AUTOSAR XML (schema 4-2-2)
package /STELLANTIS/EPT/ASWCs
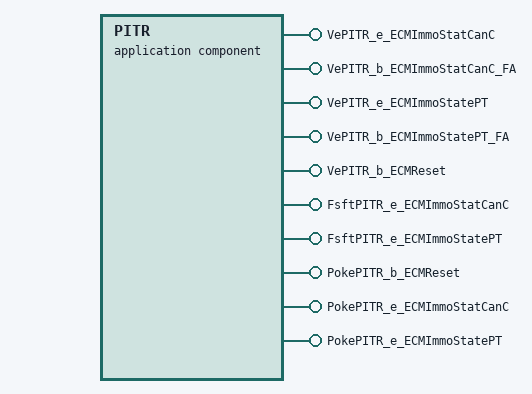
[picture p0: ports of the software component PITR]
  application sw component type PITR
    10 x provide port:
      VePITR_e_ECMImmoStatCanC: nonqueued-sender-com-spec{data-element=Value, init-value=CeIMOR_e_ECMcIS}, provided-interface=VePITR_e_ECMImmoStatCanC
      VePITR_b_ECMImmoStatCanC_FA: nonqueued-sender-com-spec{data-element=Value, init-value=0}, provided-interface=VePITR_b_ECMImmoStatCanC_FA
      VePITR_e_ECMImmoStatePT: nonqueued-sender-com-spec{data-element=Value, init-value=CeIMOR_e_ECMeIS}, provided-interface=VePITR_e_ECMImmoStatePT
      VePITR_b_ECMImmoStatePT_FA: nonqueued-sender-com-spec{data-element=Value, init-value=0}, provided-interface=VePITR_b_ECMImmoStatePT_FA
      VePITR_b_ECMReset: nonqueued-sender-com-spec{data-element=Value, init-value=0}, provided-interface=VePITR_b_ECMReset
      FsftPITR_e_ECMImmoStatCanC: server-com-spec=FsftPITR_e_ECMImmoStatCanC, provided-interface=FsftPITR_e_ECMImmoStatCanC
      FsftPITR_e_ECMImmoStatePT: server-com-spec=FsftPITR_e_ECMImmoStatePT, provided-interface=FsftPITR_e_ECMImmoStatePT
      PokePITR_b_ECMReset: server-com-spec{operation=PokePITR_b_ECMReset, queue-length=1}, provided-interface=PokePITR_b_ECMReset
      PokePITR_e_ECMImmoStatCanC: server-com-spec{operation=PokePITR_e_ECMImmoStatCanC, queue-length=1}, provided-interface=PokePITR_e_ECMImmoStatCanC
      PokePITR_e_ECMImmoStatePT: server-com-spec{operation=PokePITR_e_ECMImmoStatePT, queue-length=1}, provided-interface=PokePITR_e_ECMImmoStatePT
    behavior IB_PITR: data-type-mapping=msADTtoIDTMapping, handle-termination-and-restart=NO-SUPPORT
      5 x operation invoked event:
        Event_FsftPITR_e_ECMImmoStatCanC: start-on-event=FsftPITR_e_ECMImmoStatCanC, operation=FsftPITR_e_ECMImmoStatCanC.FsftPITR_e_ECMImmoStatCanC
        Event_FsftPITR_e_ECMImmoStatePT: start-on-event=FsftPITR_e_ECMImmoStatePT, operation=FsftPITR_e_ECMImmoStatePT.FsftPITR_e_ECMImmoStatePT
        Event_PokePITR_b_ECMReset: start-on-event=PokePITR_b_ECMReset, operation=PokePITR_b_ECMReset.PokePITR_b_ECMReset
        Event_PokePITR_e_ECMImmoStatCanC: start-on-event=PokePITR_e_ECMImmoStatCanC, operation=PokePITR_e_ECMImmoStatCanC.PokePITR_e_ECMImmoStatCanC
        Event_PokePITR_e_ECMImmoStatePT: start-on-event=PokePITR_e_ECMImmoStatePT, operation=PokePITR_e_ECMImmoStatePT.PokePITR_e_ECMImmoStatePT
      init event Event_PITR_ac_Init: start-on-event=PITR_ac_Init
      init event Event_PwrOn: start-on-event=PITR_PwrOn
      7 x runnable:
        PITR_ac_Init
          data-send-points:
            access OUT_VePITR_e_ECMImmoStatCanC_Value: accessed-variable=VePITR_e_ECMImmoStatCanC.Value
            access OUT_VePITR_e_ECMImmoStatePT_Value: accessed-variable=VePITR_e_ECMImmoStatePT.Value
        PITR_PwrOn
          data-send-points:
            5 x access:
              OUT_VePITR_b_ECMReset_Value: accessed-variable=VePITR_b_ECMReset.Value
              OUT_VePITR_e_ECMImmoStatCanC_Value: accessed-variable=VePITR_e_ECMImmoStatCanC.Value
              OUT_VePITR_b_ECMImmoStatCanC_FA_Value: accessed-variable=VePITR_b_ECMImmoStatCanC_FA.Value
              OUT_VePITR_e_ECMImmoStatePT_Value: accessed-variable=VePITR_e_ECMImmoStatePT.Value
              OUT_VePITR_b_ECMImmoStatePT_FA_Value: accessed-variable=VePITR_b_ECMImmoStatePT_FA.Value
        FsftPITR_e_ECMImmoStatCanC
          data-send-points:
            access OUT_VePITR_e_ECMImmoStatCanC_Value: accessed-variable=VePITR_e_ECMImmoStatCanC.Value
            access OUT_VePITR_b_ECMImmoStatCanC_FA_Value: accessed-variable=VePITR_b_ECMImmoStatCanC_FA.Value
        FsftPITR_e_ECMImmoStatePT
          data-send-points:
            access OUT_VePITR_e_ECMImmoStatePT_Value: accessed-variable=VePITR_e_ECMImmoStatePT.Value
            access OUT_VePITR_b_ECMImmoStatePT_FA_Value: accessed-variable=VePITR_b_ECMImmoStatePT_FA.Value
        PokePITR_b_ECMReset
          data-send-points:
            access OUT_VePITR_b_ECMReset_Value: accessed-variable=VePITR_b_ECMReset.Value
        PokePITR_e_ECMImmoStatCanC
          data-send-points:
            access OUT_VePITR_e_ECMImmoStatCanC_Value: accessed-variable=VePITR_e_ECMImmoStatCanC.Value
            access OUT_VePITR_b_ECMImmoStatCanC_FA_Value: accessed-variable=VePITR_b_ECMImmoStatCanC_FA.Value
        PokePITR_e_ECMImmoStatePT
          data-send-points:
            access OUT_VePITR_e_ECMImmoStatePT_Value: accessed-variable=VePITR_e_ECMImmoStatePT.Value
            access OUT_VePITR_b_ECMImmoStatePT_FA_Value: accessed-variable=VePITR_b_ECMImmoStatePT_FA.Value
